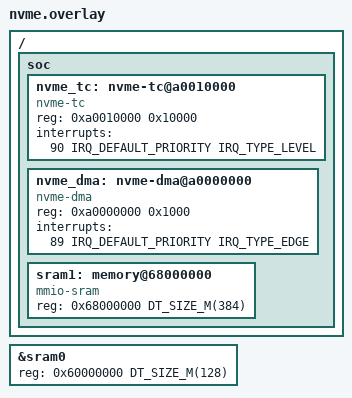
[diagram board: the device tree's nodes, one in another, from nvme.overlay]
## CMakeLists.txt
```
# Copyright 2021-2022 Western Digital Corporation or its affiliates
# Copyright 2021-2022 Antmicro

# SPDX-License-Identifier: Apache-2.0

cmake_minimum_required(VERSION 3.13.1)

set(DTC_OVERLAY_FILE "${CMAKE_CURRENT_SOURCE_DIR}/nvme.overlay")

include($ENV{ZEPHYR_BASE}/cmake/app/boilerplate.cmake NO_POLICY_SCOPE)

project(tc_sw)

target_sources(app PRIVATE src/main.c)
target_sources(app PRIVATE src/dma.c)
target_sources(app PRIVATE src/tc.c)
target_sources(app PRIVATE src/ramdisk.c)

target_sources(app PRIVATE src/rpmsg.c)
target_sources(app PRIVATE src/platform_info.c)
target_sources(app PRIVATE src/rsc_table.c)
target_sources(app PRIVATE src/zynqmp_r5_a53_rproc.c)

target_sources(app PRIVATE src/cmd.c)
target_sources(app PRIVATE src/cmds/identify.c)
target_sources(app PRIVATE src/cmds/get_log.c)
target_sources(app PRIVATE src/cmds/set_features.c)
target_sources(app PRIVATE src/cmds/queues.c)
target_sources(app PRIVATE src/cmds/read.c)
target_sources(app PRIVATE src/cmds/write.c)
target_sources(app PRIVATE src/cmds/vendor.c)

target_include_directories(app PRIVATE src)
target_include_directories(app PRIVATE ${GENERATED_DIR})

find_package( PythonInterp REQUIRED )

add_custom_target(
    generate_headers ALL
    COMMAND ${PYTHON_EXECUTABLE} ${REGGEN_DIR}/get_reg_fields.py
            ${NVME_SPEC_FILE} -f ${RPUAPP_GENERATED_DIR}/registers.json

    COMMAND ${PYTHON_EXECUTABLE} ${REGGEN_DIR}/get_reg_fields_zephyr.py
            ${RPUAPP_GENERATED_DIR}/registers.json -f ${RPUAPP_GENERATED_DIR}/nvme_reg_fields.h

    COMMAND ${PYTHON_EXECUTABLE} ${REGGEN_DIR}/get_reg_map_zephyr.py
            ${NVME_SPEC_FILE} -f ${RPUAPP_GENERATED_DIR}/nvme_reg_map.h

    COMMAND ${PYTHON_EXECUTABLE} ${REGGEN_DIR}/get_identify_struct.py
            ${NVME_SPEC_FILE} -f ${RPUAPP_GENERATED_DIR}/nvme_ident_fields.h

    BYPRODUCTS ${RPUAPP_GENERATED_DIR}/registers.json
                ${RPUAPP_GENERATED_DIR}/nvme_reg_fields.h
                ${RPUAPP_GENERATED_DIR}/nvme_reg_map.h
                ${RPUAPP_GENERATED_DIR}/nvme_ident_fields.h

    COMMENT "Generating NVMe headers"
)

add_dependencies(app generate_headers)
```

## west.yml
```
# Copyright 2021-2022 Western Digital Corporation or its affiliates
# Copyright 2021-2022 Antmicro
#
# SPDX-License-Identifier: Apache-2.0

manifest:
  defaults:
    remote: upstream

  self:
    path: rpu-app

  remotes:
    - name: upstream
      url-base: https://github.com/zephyrproject-rtos

  projects:
    - name: zephyr
      path: build/zephyr-sources/zephyr
      revision: 64dbc3e610d79db74f3ff1395fc9b1bf891f73c2
      import: true

    - name: libmetal
      revision: 6f2798ba1f6a63747baeb366ea50ccdc0cac2797
      path: build/zephyr-sources/modules/hal/libmetal
    - name: ci-tools
      revision: c083680dd5e281218ddb47d0ceac5c5fd5619749
      path: build/zephyr-sources/tools/ci-tools
    - name: net-tools
      revision: 30b7efa827b04d2e47840716b0372737fe7d6c92
      path: build/zephyr-sources/tools/net-tools
    - name: hal_atmel
      revision: 5690f5b84495c8b657ff204c5c827df1ab9e12e3
      path: build/zephyr-sources/modules/hal/atmel
    - name: civetweb
      revision: 99129c5efc907ea613c4b73ccff07581feb58a7a
      path: build/zephyr-sources/modules/lib/civetweb
    - name: esp-idf
      revision: 6835bfc741bf15e98fb7971293913f770df6081f
      path: build/zephyr-sources/modules/hal/esp-idf
    - name: fatfs
      revision: df96914dd989907f3a5de4cb95b116c2f305820d
      path: build/zephyr-sources/modules/fs/fatfs
    - name: hal_cypress
      revision: a12d92816a53a521d79cefcf5c38b9dc8a4fed6e
      path: build/zephyr-sources/modules/hal/cypress
    - name: hal_nordic
      revision: 64f3473398f9fba11059dd0c7ae969e74f74f356
      path: build/zephyr-sources/modules/hal/nordic
    - name: hal_openisa
      revision: 6416140c00f7e663752bd420ba89e3caefc1d70e
      path: build/zephyr-sources/modules/hal/openisa
    - name: hal_microchip
      revision: 85302959c0c659311cf90ac51d133e5ce19c9288
      path: build/zephyr-sources/modules/hal/microchip
    - name: hal_silabs
      revision: 9151e614c23997074acd1096a3e8a9e5c255d5b9
      path: build/zephyr-sources/modules/hal/silabs
    - name: hal_st
      revision: fa481784b3c49780f18d50bafe00390ccb62b2ec
      path: build/zephyr-sources/modules/hal/st
    - name: hal_stm32
      revision: 20776221282b6447c6330a041bc27758c8f593f3
      path: build/zephyr-sources/modules/hal/stm32
    - name: hal_ti
      revision: 7a82e93e14766ef6e42df9915ea2ab8e3b952a8b
      path: build/zephyr-sources/modules/hal/ti
    - name: lvgl
      revision: d4708d0a432e95f51bdc712591ba5295b751140c
      path: build/zephyr-sources/modules/lib/gui/lvgl
    - name: mbedtls
      revision: 4f1e8f5a78dc08aa42a47cc1ad059cce558c26c3
      path: build/zephyr-sources/modules/crypto/mbedtls
    - name: mcumgr
      revision: 84934959d2d1722a23b7e7e200191ae4a6f96168
      path: build/zephyr-sources/modules/lib/mcumgr
    - name: nffs
      revision: bc62a2fa9d98ddb5d633c932ea199bc68e10f194
      path: build/zephyr-sources/modules/fs/nffs
    - name: hal_nxp
      revision: c6ce9b7e8ddb501ca6d54e927e1602cb5f7a7183
      path: build/zephyr-sources/modules/hal/nxp
    - name: open-amp
      revision: 9b591b289e1f37339bd038b5a1f0e6c8ad39c63a
      path: build/zephyr-sources/modules/lib/open-amp
    - name: openthread
      revision: 882e7074b5986027b85cb4f3ba1dc563a11ca013
      path: build/zephyr-sources/modules/lib/openthread
    - name: segger
      revision: 6fcf61606d6012d2c44129edc033f59331e268bc
      path: build/zephyr-sources/modules/debug/segger
    - name: tinycbor
      path: build/zephyr-sources/modules/lib/tinycbor
      revision: 0fc68fceacd1efc1ce809c5880c380f3d98b7b6e
    - name: littlefs
      path: build/zephyr-sources/modules/fs/littlefs
      revision: fe9572dd5a9fcf93a249daa4233012692bd2881d
    - name: mipi-sys-t
      path: build/zephyr-sources/modules/debug/mipi-sys-t
      revision: baf51863f19f009b92e762115ba5572a5b996b92
```

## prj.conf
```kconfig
CONFIG_NEWLIB_LIBC=y
CONFIG_OPENAMP=y
CONFIG_HEAP_MEM_POOL_SIZE=4096
CONFIG_IPM=y
CONFIG_IPM_XLNX_ZYNQMP=y
CONFIG_LOG=y
CONFIG_LOG_MAX_LEVEL=4
CONFIG_LOG_BUFFER_SIZE=65536
CONFIG_LOG_FUNC_NAME_PREFIX_ERR=y
CONFIG_LOG_FUNC_NAME_PREFIX_WRN=y
CONFIG_LOG_FUNC_NAME_PREFIX_INF=y
CONFIG_LOG_FUNC_NAME_PREFIX_DBG=y
```

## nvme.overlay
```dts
/ {
	soc {
		nvme_tc: nvme-tc@a0010000 {
			compatible = "nvme-tc";
			reg = <0xa0010000 0x10000>;
			status = "okay";
			interrupts = <90 IRQ_DEFAULT_PRIORITY IRQ_TYPE_LEVEL>;
			interrupt-names = "host_write";
		};

		nvme_dma: nvme-dma@a0000000 {
			compatible = "nvme-dma";
			reg = <0xa0000000 0x1000>;
			status = "okay";
			interrupts = <89 IRQ_DEFAULT_PRIORITY IRQ_TYPE_EDGE>;
			interrupt-names = "dma_done";
		};

		sram1: memory@68000000 {
			compatible = "mmio-sram";
			reg = <0x68000000 DT_SIZE_M(384)>;
		};
	};
};

&sram0 {
	reg = <0x60000000 DT_SIZE_M(128)>;
};
```

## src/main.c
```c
/*
 * Copyright 2021-2022 Western Digital Corporation or its affiliates
 * Copyright 2021-2022 Antmicro
 *
 * SPDX-License-Identifier: Apache-2.0
 */

#include <zephyr.h>
#include <sys/printk.h>
#include <irq.h>

#include "main.h"
#include "dma.h"
#include "tc.h"
#include "ramdisk.h"
#include "rpmsg.h"

#include "platform_info.h"

#include <string.h>

#include <logging/log_ctrl.h>
#include <logging/log.h>

LOG_MODULE_REGISTER(NVME_LOGGER_NAME, NVME_LOGGER_LEVEL);
K_MEM_POOL_DEFINE(buffer_pool, PAGE_SIZE, NVME_BUFFER_SIZE, NVME_BUFFER_POOL_ENTRIES, PAGE_SIZE);

nvme_tc_priv_t *init(void)
{
	ramdisk_init();
	LOG_DBG("Init [1/6]: Ramdisk initialized");

	void *dma_priv = nvme_dma_init();
	LOG_DBG("Init [2/6]: DMA initialized");

	nvme_tc_priv_t *tc = nvme_tc_init(dma_priv);
	tc->buffer_pool = &buffer_pool;
	LOG_DBG("Init [3/6]: Target Controller (TC) initialized");

	nvme_dma_irq_init();
	LOG_DBG("Init [4/6]: DMA IRQ initialized");

	nvme_tc_irq_init();
	LOG_DBG("Init [5/6]: TC IRQs initialized");

	rpmsg_init(tc);
	LOG_DBG("Init [6/6]: Rpmsg initialized");

	return tc;
}

void main(void)
{
	log_init();
	LOG_INF("NVMe Controller FW for %s", CONFIG_BOARD);

	nvme_tc_priv_t *tc = init();

	LOG_INF("NVMe controller initialized");

	while(1) {
		platform_poll(tc->platform);
		k_sleep(100);
	}

	rpmsg_destroy_ept(&tc->lept);
}
```

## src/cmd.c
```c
/*
 * Copyright 2021-2022 Western Digital Corporation or its affiliates
 * Copyright 2021-2022 Antmicro
 *
 * SPDX-License-Identifier: Apache-2.0
 */

#include "cmd.h"
#include "dma.h"
#include "main.h"

#include <zephyr.h>
#include <sys/printk.h>
#include <openamp/open_amp.h>

#include <logging/log.h>
LOG_MODULE_DECLARE(NVME_LOGGER_NAME, NVME_LOGGER_LEVEL);

static inline void fill_cq_resp(nvme_cmd_priv_t *priv)
{
	nvme_sq_entry_base_t *sq = (nvme_sq_entry_base_t*)priv->sq_buf;
	nvme_cq_entry_t *cq = (nvme_cq_entry_t*)&priv->cq_buf;

	memset((void*)cq, 0, NVME_TC_CQ_ENTRY_SIZE);
	cq->sq_head = priv->tc->sq_head[priv->qid];
	cq->cid = sq->cdw0.cid;
}

static void handle_adm(nvme_cmd_priv_t *priv)
{
	nvme_sq_entry_base_t *cmd = (nvme_sq_entry_base_t*)priv->sq_buf;

	// LOG_DBG("Admin command (Opcode: %d)", cmd->cdw0.opc);
	switch(cmd->cdw0.opc) {
		case NVME_ADM_CMD_GET_LOG:
			LOG_DBG("Handling NVME_ADM_CMD_GET_LOG");
			nvme_cmd_adm_get_log(priv);
			break;
		case NVME_ADM_CMD_IDENTIFY:
			LOG_DBG("Handling NVME_ADM_CMD_IDENTIFY");
			nvme_cmd_adm_identify(priv);
			break;
		case NVME_ADM_CMD_SET_FEATURES:
			LOG_DBG("Handling NVME_ADM_CMD_SET_FEATURES");
			nvme_cmd_adm_set_features(priv);
			break;
		case NVME_ADM_CMD_CREATE_IO_SQ:
			LOG_DBG("Handling NVME_ADM_CMD_CREATE_IO_SQ");
			nvme_cmd_adm_create_sq(priv);
			break;
		case NVME_ADM_CMD_CREATE_IO_CQ:
			LOG_DBG("Handling NVME_ADM_CMD_CREATE_IO_CQ");
			nvme_cmd_adm_create_cq(priv);
			break;
		case NVME_ADM_CMD_DELETE_IO_SQ:
			LOG_DBG("Handling NVME_ADM_CMD_DELETE_IO_SQ");
			nvme_cmd_adm_delete_sq(priv);
			break;
		case NVME_ADM_CMD_DELETE_IO_CQ:
			LOG_DBG("Handling NVME_ADM_CMD_DELETE_IO_CQ");
			nvme_cmd_adm_delete_cq(priv);
			break;
		case NVME_ADM_CMD_FW_COMMIT: // Vendor command layout is compatible with FW commands and in the end FW commands are handled by the APU
			LOG_DBG("Handling NVME_ADM_CMD_FW_COMMIT");
			nvme_cmd_vendor(priv, 0);
			break;
		case NVME_ADM_CMD_FW_DOWNLOAD:
			LOG_DBG("Handling NVME_ADM_CMD_FW_DOWNLOAD");
			nvme_cmd_vendor(priv, 1);
			break;
		case NVME_ADM_CMD_KEEP_ALIVE:
			LOG_DBG("Handling NVME_ADM_CMD_KEEP_ALIVE");
		default:
			if(cmd->cdw0.opc >= NVME_ADM_CMD_VENDOR) {
				LOG_DBG("Handling NVME_ADM_CMD_VENDOR");
				nvme_cmd_vendor(priv, 0);
				break;
			}
			LOG_ERR("Unsupported Admin command! (Opcode: %d)", cmd->cdw0.opc);
			nvme_cmd_return(priv);
	}
}

static void handle_io(nvme_cmd_priv_t *priv)
{
	nvme_sq_entry_base_t *cmd = (nvme_sq_entry_base_t*)priv->sq_buf;

	// LOD_DBG("IO command (Opcode: %d)", cmd->cdw0.opc);
	switch(cmd->cdw0.opc) {
		case NVME_IO_CMD_FLUSH:
			LOG_DBG("Handling NVME_IO_CMD_FLUSH");
			nvme_cmd_return(priv);
			break;
		case NVME_IO_CMD_WRITE:
			LOG_DBG("Handling NVME_IO_CMD_WRITE");
			nvme_cmd_io_write(priv);
			break;
		case NVME_IO_CMD_READ:
			LOG_DBG("Handling NVME_IO_CMD_READ");
			nvme_cmd_io_read(priv);
			break;
		default:
			if(cmd->cdw0.opc >= NVME_IO_CMD_VENDOR) {
				LOG_DBG("Handling NVME_IO_CMD_VENDOR");
				nvme_cmd_vendor(priv, 0);
				break;
			}
			LOG_ERR("Unsupported IO Command! (Opcode: %d)", cmd->cdw0.opc);
			nvme_cmd_return(priv);
	}
}

void nvme_cmd_handler(void *cmd_priv, void *buf)
{
	nvme_cmd_priv_t *priv = (nvme_cmd_priv_t*)cmd_priv;
	fill_cq_resp(priv);

	if(priv->qid == ADM_QUEUE_ID)
		handle_adm(priv);
	else
		handle_io(priv);
}

static void cq_cb(void *cmd_priv, void *buf)
{
	nvme_cmd_priv_t *priv = (nvme_cmd_priv_t*)cmd_priv;
	LOG_INF("Sending completion interrupt to host");
	nvme_tc_cq_notify(priv->tc, priv->qid);
	k_mem_slab_free(&priv->tc->cmd_slab, &cmd_priv);
}

void nvme_cmd_return_cb(void *cmd_priv, void *buf)
{
	nvme_cmd_priv_t *priv = (nvme_cmd_priv_t*)cmd_priv;
	nvme_cmd_return(priv);
}

void nvme_cmd_return(nvme_cmd_priv_t *priv)
{
	nvme_cq_entry_t *cq = (nvme_cq_entry_t*)&priv->cq_buf;

	uint64_t cq_addr = nvme_tc_get_cq_addr(priv->tc, priv->qid);

	if (!cq_addr) {
		LOG_ERR("Completion Queue host memory address is invalid!");
		return;
	}

	// We know the correct phase only after obtaining next CQ entry address
	cq->p = priv->tc->cq_phase[priv->qid];

	nvme_dma_xfer_mem_to_host(priv->tc->dma_priv, (uint32_t)cq, cq_addr, NVME_TC_CQ_ENTRY_SIZE, cq_cb, (void*)priv);
}

static void transfer_chunk(nvme_cmd_priv_t *priv, uint64_t host_addr, uint32_t local_addr, uint32_t len)
{
	nvme_dma_xfer_cb *cb = NULL;
	void *arg = NULL;

	// const uint32_t lo = host_addr & 0xffffffff;
	// const uint32_t hi = (host_addr >> 32) & 0xffffffff;
	// LOG_DBG("Transferring data, host: %08x %08x, local: %08x, len: %d", hi, lo, local_addr, len);

	if(priv->xfer_len == len) {
		cb = priv->xfer_cb;
		arg = priv;
	}

	if(priv->dir == DIR_TO_HOST) {
		nvme_dma_xfer_mem_to_host(priv->tc->dma_priv, local_addr, host_addr, len, cb, arg);
	} else {
		nvme_dma_xfer_host_to_mem(priv->tc->dma_priv, host_addr, local_addr, len, cb, arg);
	}

	priv->xfer_len -= len;
	priv->xfer_buf += len;
}

static uint32_t calc_prp_size(uint64_t base, uint32_t mps, uint32_t len)
{
	uint32_t total = ((len + mps - 1) / mps) * sizeof(uint64_t);
	uint32_t page = mps - (base % mps);
	return (page > total) ? total : page;
}

static void prp_cb(void *cmd_priv, void *buf)
{
	nvme_cmd_priv_t *priv = (nvme_cmd_priv_t*)cmd_priv;
	uint64_t *prp_list = (uint64_t*)buf;
	const uint32_t mps = priv->tc->memory_page_size;
	const int prp_last = (priv->prp_size / sizeof(uint64_t)) - 1;
	int i = 0;

	LOG_DBG("List of PRPs transferred");

	while(priv->xfer_len > 0) {
		const int xfer_len = (mps > priv->xfer_len) ? priv->xfer_len : mps;

		if((i == prp_last) && (priv->xfer_len > mps)) { // We need to fetch another PRP list
			priv->prp_size = calc_prp_size(prp_list[prp_last], mps, priv->xfer_len);
			nvme_dma_xfer_host_to_mem(priv->tc->dma_priv, prp_list[prp_last], (uint32_t)buf, priv->prp_size, prp_cb, priv);
			LOG_DBG("Fetching list of PRPs (%d bytes)", priv->prp_size);
			return;
		}

		transfer_chunk(priv, prp_list[i++], priv->xfer_buf, xfer_len);
	}

	LOG_DBG("Finished transferring %d pages", i);

	k_mem_slab_free(&priv->tc->prp_slab, &buf);
}

static void transfer_data_with_prps(nvme_cmd_priv_t *priv)
{
	nvme_sq_entry_base_t *cmd = (nvme_sq_entry_base_t*)priv->sq_buf;
	uint64_t host_addr = cmd->dptr.prp.prp1;
	const int mps = priv->tc->memory_page_size;
	const int off = host_addr % mps;

	uint32_t xfer_len = ((mps - off) > priv->xfer_len) ? priv->xfer_len : (mps - off);

	transfer_chunk(priv, host_addr, priv->xfer_buf, xfer_len);

    printk("transfer_data_with_prps()\n"); // FIXME: This is a temporary workaround for a race condition.

	if(priv->xfer_len == 0) {
		return;
	}

	if(priv->xfer_len > mps) { // We need to fetch list of PRPs
		void *prp_buf;
		if(k_mem_slab_alloc(&priv->tc->prp_slab, (void**)&prp_buf, K_NO_WAIT) == 0) {
			priv->prp_size = calc_prp_size(cmd->dptr.prp.prp2, mps, priv->xfer_len);
			nvme_dma_xfer_host_to_mem(priv->tc->dma_priv, cmd->dptr.prp.prp2, (uint32_t)prp_buf, priv->prp_size, prp_cb, priv);
			LOG_DBG("Fetching list of PRPs (%d bytes)", priv->prp_size);
			return;
		} else {
			LOG_ERR("Failed to allocate PRP buffer!");
			nvme_cmd_return(priv);
			return;
		}
	} else { // Second PRP is in PRP2
		host_addr = cmd->dptr.prp.prp2;
		xfer_len = priv->xfer_len;
		transfer_chunk(priv, host_addr, priv->xfer_buf, xfer_len);
		return;
	}
}

int nvme_cmd_transfer_data(nvme_cmd_priv_t *priv)
{
	nvme_sq_entry_base_t *cmd = (nvme_sq_entry_base_t*)priv->sq_buf;
	uint8_t psdt = cmd->cdw0.psdt;

	if(psdt != 0) {
		LOG_ERR("Invalid PSDT value! (%d != 0)", psdt);
		return 1;
	} else {
		transfer_data_with_prps(priv);
		return 0;
	}

}

void nvme_cmd_get_data(nvme_cmd_priv_t *priv, void *ret_buf, uint32_t ret_len)
{
	priv->xfer_base = priv->xfer_buf = (uint32_t)ret_buf;
	priv->xfer_size = priv->xfer_len = ret_len;

	priv->dir = DIR_FROM_HOST;
	priv->xfer_cb = nvme_cmd_return_cb;

	if(nvme_cmd_transfer_data(priv))
		nvme_cmd_return(priv);
}

void nvme_cmd_return_data(nvme_cmd_priv_t *priv, void *ret_buf, uint32_t ret_len)
{
	priv->xfer_base = priv->xfer_buf = (uint32_t)ret_buf;
	priv->xfer_size = priv->xfer_len = ret_len;

	priv->dir = DIR_TO_HOST;
	priv->xfer_cb = nvme_cmd_return_cb;

	if(nvme_cmd_transfer_data(priv))
		nvme_cmd_return(priv);
}
```

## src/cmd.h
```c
/*
 * Copyright 2021-2022 Western Digital Corporation or its affiliates
 * Copyright 2021-2022 Antmicro
 *
 * SPDX-License-Identifier: Apache-2.0
 */

#ifndef NVME_CMD_H
#define NVME_CMD_H

#include <stdint.h>
#include <string.h>

#include "tc.h"

void nvme_cmd_handler(void *cmd_priv, void *cmd);

typedef struct nvme_cmd_cdw0 {
	uint32_t opc : 8;
	uint32_t fuse : 2;
	uint32_t rsvd : 4;
	uint32_t psdt : 2;
	uint32_t cid : 16;
} nvme_cmd_cdw0_t;

typedef struct nvme_cmd_prp {
	uint64_t prp1;
	uint64_t prp2;
} nvme_cmd_prp_t;

typedef struct __attribute__((packed)) nvme_cmd_sgl {
	uint8_t sgl_desc_type : 4;
	uint8_t sgl_desc_sub_type : 4;
	uint8_t rsvd[15];
} nvme_cmd_sgl_t;

typedef union nvme_cmd_dptr {
	nvme_cmd_prp_t prp;
	nvme_cmd_sgl_t sgl;
} nvme_cmd_dptr_t;

typedef struct nvme_sq_entry_base {
	nvme_cmd_cdw0_t cdw0;
	uint32_t nsid;
	uint32_t rsvd[2];
	uint64_t mptr;
	nvme_cmd_dptr_t dptr;
} nvme_sq_entry_base_t;

typedef struct nvme_sq_entry_vendor_base {
	nvme_sq_entry_base_t base;
	uint32_t ndt;
	uint32_t ndm;
} nvme_sq_entry_vendor_base_t;

typedef struct nvme_cq_entry {
	uint32_t cdw0;
	uint32_t rsvd;
	uint32_t sq_head : 16;
	uint32_t sq_id : 16;
	uint32_t cid : 16;
	uint32_t p : 1;
	uint32_t sc : 8;
	uint32_t sct : 3;
	uint32_t crd : 2;
	uint32_t m : 1;
	uint32_t dnr : 1;
} nvme_cq_entry_t;

#define NVME_ADM_CMD_GET_LOG		0x02
#define NVME_ADM_CMD_IDENTIFY		0x06
#define NVME_ADM_CMD_SET_FEATURES	0x09
#define NVME_ADM_CMD_CREATE_IO_SQ	0x01
#define NVME_ADM_CMD_CREATE_IO_CQ	0x05
#define NVME_ADM_CMD_DELETE_IO_SQ	0x00
#define NVME_ADM_CMD_DELETE_IO_CQ	0x04
#define NVME_ADM_CMD_FW_COMMIT		0x10
#define NVME_ADM_CMD_FW_DOWNLOAD	0x11
#define NVME_ADM_CMD_KEEP_ALIVE		0x18

#define NVME_ADM_CMD_VENDOR		0xC0

#define NVME_IO_CMD_FLUSH		0x00
#define NVME_IO_CMD_WRITE		0x01
#define NVME_IO_CMD_READ		0x02

#define NVME_IO_CMD_VENDOR		0x80

#define NVME_CMD_XFER_NONE		0x00
#define NVME_CMD_XFER_FROM_HOST		0x01
#define NVME_CMD_XFER_TO_HOST		0x02
#define NVME_CMD_XFER_BIDIR		0x03
#define NVME_CMD_XFER_MASK		0x03

int nvme_cmd_transfer_data(nvme_cmd_priv_t *priv);

void nvme_cmd_vendor(nvme_cmd_priv_t *priv, int zero_based);

void nvme_cmd_adm_identify(nvme_cmd_priv_t *priv);
void nvme_cmd_adm_get_log(nvme_cmd_priv_t *priv);
void nvme_cmd_adm_set_features(nvme_cmd_priv_t *priv);

void nvme_cmd_adm_create_sq(nvme_cmd_priv_t *priv);
void nvme_cmd_adm_create_cq(nvme_cmd_priv_t *priv);

void nvme_cmd_adm_delete_sq(nvme_cmd_priv_t *priv);
void nvme_cmd_adm_delete_cq(nvme_cmd_priv_t *priv);

void nvme_cmd_io_write(nvme_cmd_priv_t *priv);
void nvme_cmd_io_read(nvme_cmd_priv_t *priv);

void nvme_cmd_return(nvme_cmd_priv_t *priv);
void nvme_cmd_return_data(nvme_cmd_priv_t *priv, void *ret_buf, uint32_t ret_len);
void nvme_cmd_get_data(nvme_cmd_priv_t *priv, void *ret_buf, uint32_t ret_len);

#endif
```

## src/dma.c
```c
/*
 * Copyright 2021-2022 Western Digital Corporation or its affiliates
 * Copyright 2021-2022 Antmicro
 *
 * SPDX-License-Identifier: Apache-2.0
 */

#include "dma.h"
#include <zephyr.h>
#include <sys/printk.h>
#include <string.h>

#define DEBUG

typedef struct nvme_dma_priv {
	mem_addr_t base;

	uint32_t tx_xfers;
	uint32_t rx_xfers;

	struct k_fifo tx_fifo;
	struct k_fifo rx_fifo;

	bool tx_dma_running;
	bool rx_dma_running;

	struct k_mem_slab desc_slab;
} nvme_dma_priv_t;

typedef struct nvme_dma_xfer_def {
	void *fifo_reserved;
	nvme_dma_xfer_cb *cb;
	void *cb_arg;
	uint64_t host_addr;
	uint32_t local_addr;
	uint32_t len;
	uint32_t tag;
} nvme_dma_xfer_def_t;

nvme_dma_priv_t p_dma = {0};

char __aligned(16) desc_slab_buffer[sizeof(nvme_dma_xfer_def_t)*NVME_DMA_SLAB_ENTRIES];

struct k_timer nvme_dma_timer; // DMA timeout timer

static void nvme_dma_timeout (struct k_timer *timer) {

	nvme_dma_priv_t *priv = (nvme_dma_priv_t*)k_timer_user_data_get(timer);
	unsigned long long lock;

	LOG_ERR("DMA interrupt timeout!");

	lock = irq_lock();
	priv->rx_dma_running = false;
	// TODO: Retry transfer? Do something meaningful?
	irq_unlock(lock);

	k_timer_stop(timer);
}

static void nvme_dma_setup_xfer(nvme_dma_priv_t *priv, nvme_dma_xfer_def_t *desc, uint32_t off)
{
#ifdef DEBUG
	printk("Configuring DMA transfer\n");
#endif

	__DMB();

	sys_write32(desc->host_addr & 0xffffffff, priv->base + off + NVME_DMA_REG_PCIE_ADDRL);
	sys_write32((desc->host_addr >> 32) & 0xffffffff, priv->base + off + NVME_DMA_REG_PCIE_ADDRH);

	// We use 32-bit AXI addresses, upper 32-bits are ignored
	sys_write32(desc->local_addr, priv->base + off + NVME_DMA_REG_AXI_ADDRL);
	sys_write32(0, priv->base + off + NVME_DMA_REG_AXI_ADDRH);

	sys_write32(desc->len, priv->base + off + NVME_DMA_REG_LEN);

	// Writing tag starts transfer
	sys_write32(desc->tag, priv->base + off + NVME_DMA_REG_TAG);

	// Start the timeout timer
	// FIXME: Resolve the issue with incorrect CPU frequency set in Zephyr
	// and change the delay to something meaningful.
	k_timer_start(&nvme_dma_timer, K_SECONDS(100), K_FOREVER);
}

void nvme_dma_irq_handler(void *arg)
{
	nvme_dma_priv_t *priv = (nvme_dma_priv_t*)arg;
	unsigned long long lock;

	uint32_t read_status = sys_read32(priv->base + NVME_DMA_REG_STATUS + NVME_DMA_REG_READ_BASE);
	uint32_t write_status = sys_read32(priv->base + NVME_DMA_REG_STATUS + NVME_DMA_REG_WRITE_BASE);

	if(read_status & NVME_DMA_REG_STATUS_VALID) {
		nvme_dma_xfer_def_t *desc = k_fifo_get(&priv->rx_fifo, K_NO_WAIT);
		if(desc) {
			if(desc->cb)
				desc->cb(desc->cb_arg, (void*)desc->local_addr);
			k_mem_slab_free(&priv->desc_slab, (void**)&desc);
		} else {
			printk("Spurious DMA RX interrupt!\n");
		}

		lock = irq_lock();

		// Check if there is another transfer pending
		desc = k_fifo_peek_head(&priv->rx_fifo);
		if(desc)
			nvme_dma_setup_xfer(priv, desc, NVME_DMA_REG_READ_BASE);
		else {
			priv->rx_dma_running = false;
			k_timer_stop(&nvme_dma_timer);
		}

		irq_unlock(lock);
	}

	if(write_status & NVME_DMA_REG_STATUS_VALID) {
		nvme_dma_xfer_def_t *desc = k_fifo_get(&priv->tx_fifo, K_NO_WAIT);
		if(desc) {
			if(desc->cb)
				desc->cb(desc->cb_arg, (void*)desc->local_addr);
			k_mem_slab_free(&priv->desc_slab, (void**)&desc);
		} else {
			printk("Spurious DMA TX interrupt!\n");
		}

		lock = irq_lock();

		// Check if there is another transfer pending
		desc = k_fifo_peek_head(&priv->tx_fifo);
		if(desc)
			nvme_dma_setup_xfer(priv, desc, NVME_DMA_REG_WRITE_BASE);
		else {
			priv->tx_dma_running = false;
			k_timer_stop(&nvme_dma_timer);
		}

		irq_unlock(lock);
	}
}

void nvme_dma_irq_init(void)
{
	printk("Enabling DMA interrupts\n");
	IRQ_CONNECT(DT_INST_0_NVME_DMA_IRQ_0, DT_INST_0_NVME_DMA_IRQ_0_PRIORITY, nvme_dma_irq_handler, &p_dma, DT_INST_0_NVME_DMA_IRQ_0_FLAGS);
	irq_enable(DT_INST_0_NVME_DMA_IRQ_0);
	printk("DMA interrupts enabled\n");
}

void *nvme_dma_init(void)
{
	nvme_dma_priv_t *priv = &p_dma;

	priv->base = (mem_addr_t)DT_INST_0_NVME_DMA_BASE_ADDRESS;

	printk("Initializing private data\n");

	k_fifo_init(&priv->tx_fifo);
	k_fifo_init(&priv->rx_fifo);
	k_mem_slab_init(&priv->desc_slab, desc_slab_buffer, sizeof(nvme_dma_xfer_def_t), NVME_DMA_SLAB_ENTRIES);

	printk("Enabling DMA\n");
	sys_write32(1, priv->base + NVME_DMA_REG_EN);

	if(sys_read32(priv->base + NVME_DMA_REG_EN) == 1)
		printk("DMA enabled\n");
	else
		printk("Failed to enable DMA!\n");

	k_timer_init(&nvme_dma_timer, nvme_dma_timeout, NULL);
	k_timer_user_data_set(&nvme_dma_timer, (void*)priv);

	return (void*)priv;
}

static nvme_dma_xfer_def_t *nvme_dma_xfer_fill_desc(nvme_dma_priv_t *priv, uint64_t host, uint32_t local, uint32_t len, uint32_t tag, nvme_dma_xfer_cb *cb, void *cb_arg)
{
	nvme_dma_xfer_def_t *desc;

	if(k_mem_slab_alloc(&priv->desc_slab, (void**)&desc, K_NO_WAIT) == 0) {
		memset(desc, 0, sizeof(*desc));

		desc->host_addr = host;
		desc->local_addr = local;
		desc->len = len;
		desc->cb = cb;
		desc->cb_arg = cb_arg;
		desc->tag = tag;
	} else {
		printk("Failed to allocate DMA descriptor!\n");
		return NULL;
	}

	return desc;
}

int nvme_dma_xfer_host_to_mem(void* arg, uint64_t src, uint32_t dst, uint32_t len, nvme_dma_xfer_cb *cb, void *cb_arg)
{
	nvme_dma_priv_t *priv = (nvme_dma_priv_t*)arg;
	nvme_dma_xfer_def_t *desc = nvme_dma_xfer_fill_desc(priv, src, dst, len, 0xAA, cb, cb_arg);
	unsigned long long lock;

	printk("%s\n", __FUNCTION__);
	if(desc) {
		lock = irq_lock();
		k_fifo_put(&priv->rx_fifo, desc);
		if(!priv->rx_dma_running) {
			nvme_dma_setup_xfer(priv, desc, NVME_DMA_REG_READ_BASE);
			priv->rx_dma_running = true;
		}
		irq_unlock(lock);
		return 0;
	} else {
		return -ENOMEM;
	}
}

int nvme_dma_xfer_mem_to_host(void* arg, uint32_t src, uint64_t dst, uint32_t len, nvme_dma_xfer_cb *cb, void *cb_arg)
{
	nvme_dma_priv_t *priv = (nvme_dma_priv_t*)arg;
	nvme_dma_xfer_def_t *desc = nvme_dma_xfer_fill_desc(priv, dst, src, len, 0x55, cb, cb_arg);
	unsigned long long lock;

	if(desc) {
		lock = irq_lock();
		k_fifo_put(&priv->tx_fifo, desc);
		if(!priv->tx_dma_running) {
			nvme_dma_setup_xfer(priv, desc, NVME_DMA_REG_WRITE_BASE);
			priv->tx_dma_running = true;
		}
		irq_unlock(lock);
		return 0;
	} else {
		return -ENOMEM;
	}
}
```

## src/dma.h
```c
/*
 * Copyright 2021-2022 Western Digital Corporation or its affiliates
 * Copyright 2021-2022 Antmicro
 *
 * SPDX-License-Identifier: Apache-2.0
 */

#ifndef NVME_DMA_H
#define NVME_DMA_H

#define NVME_DMA_REG_EN	0x000

#define NVME_DMA_REG_READ_BASE		0x100
#define NVME_DMA_REG_WRITE_BASE		0x200

#define NVME_DMA_REG_PCIE_ADDRL		0x00
#define NVME_DMA_REG_PCIE_ADDRH		0x04
#define NVME_DMA_REG_AXI_ADDRL		0x08
#define NVME_DMA_REG_AXI_ADDRH		0x0c
#define NVME_DMA_REG_LEN		0x10
#define NVME_DMA_REG_TAG		0x14
#define NVME_DMA_REG_STATUS		0x18
#define NVME_DMA_REG_STATUS_VALID	(1<<31)

#define NVME_DMA_REG_RQ_COUNT		0x400
#define NVME_DMA_REG_RC_COUNT		0x404
#define NVME_DMA_REG_CQ_COUNT		0x408
#define NVME_DMA_REG_CC_COUNT		0x40c

#define NVME_DMA_SLAB_ENTRIES		(4096*16)

#include <stdint.h>

typedef void (nvme_dma_xfer_cb)(void *arg, void *buf);

void nvme_dma_irq_init(void);
void *nvme_dma_init(void);
int nvme_dma_xfer_host_to_mem(void *arg, uint64_t src, uint32_t dst, uint32_t len, nvme_dma_xfer_cb *cb, void *cb_arg);
int nvme_dma_xfer_mem_to_host(void *arg, uint32_t src, uint64_t dst, uint32_t len, nvme_dma_xfer_cb *cb, void *cb_arg);

#endif
```

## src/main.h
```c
#ifndef MAIN_H
#define MAIN_H

#define NVME_LOGGER_NAME  nvme
#define NVME_LOGGER_LEVEL 4

#endif /* MAIN_H */
```

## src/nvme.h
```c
#ifndef NVME_H
#define NVME_H

#include "nvme_reg_map.h"
#include "nvme_reg_fields.h"

#define DOORBELLS		5

#define DOORBELL_BASE		0x1000

#define DOORBELL_REG(n)		(DOORBELL_BASE+(n)*4)

#define DOORBELL_TAIL(n)	(DOORBELL_REG((n*2)))
#define DOORBELL_HEAD(n)	(DOORBELL_REG((n*2)+1))

#define NVME_TC_REG_ADM_TAIL	(DOORBELL_TAIL(0))
#define NVME_TC_REG_ADM_HEAD	(DOORBELL_HEAD(0))

#define NVME_TC_REG_IO_TAIL(n)	(DOORBELL_TAIL(n+1))
#define NVME_TC_REG_IO_HEAD(n)	(DOORBELL_HEAD(n+1))

#define NVME_TC_REG_IRQ_STA	(DOORBELL_TAIL(DOORBELLS))
#define NVME_TC_REG_IRQ_DAT	(DOORBELL_HEAD(DOORBELLS))

#define NVME_GET_FIELD(reg,name)	(((reg) >> NVME_TC_REG_##name##_SHIFT) & NVME_TC_REG_##name##_MASK)

#define NVME_SET_FIELD(reg, val, name)	(reg) |= (((val) & NVME_TC_REG_##name##_MASK) << NVME_TC_REG_##name##_SHIFT)

#define NVME_CLR_FIELD(reg, name)	NVME_SET_FIELD(reg, 0, name)

#define NVME_SHUTDOWN_PROCESSING	0x1
#define NVME_SHUTDOWN_COMPLETE		0x2

#endif
```

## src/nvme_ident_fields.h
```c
// Generated on 05/05/2021 10:16:15 with get_identify_struct.py, git rev 91c05fe
#ifndef NVME_IDENT_FIELDS_H
#define NVME_IDENT_FIELDS_H

#define	NVME_ID_FIELD_VID	0x0
#define	NVME_ID_FIELD_VID_SIZE	2
#define	NVME_ID_FIELD_SSVID	0x2
#define	NVME_ID_FIELD_SSVID_SIZE	2
#define	NVME_ID_FIELD_SN	0x4
#define	NVME_ID_FIELD_SN_SIZE	20
#define	NVME_ID_FIELD_MN	0x18
#define	NVME_ID_FIELD_MN_SIZE	40
#define	NVME_ID_FIELD_FR	0x40
#define	NVME_ID_FIELD_FR_SIZE	8
#define	NVME_ID_FIELD_RAB	0x48
#define	NVME_ID_FIELD_RAB_SIZE	1
#define	NVME_ID_FIELD_IEEE	0x49
#define	NVME_ID_FIELD_IEEE_SIZE	3
#define	NVME_ID_FIELD_CMIC	0x4c
#define	NVME_ID_FIELD_CMIC_SIZE	1
#define	NVME_ID_FIELD_MDTS	0x4d
#define	NVME_ID_FIELD_MDTS_SIZE	1
#define	NVME_ID_FIELD_CNTLID	0x4e
#define	NVME_ID_FIELD_CNTLID_SIZE	2
#define	NVME_ID_FIELD_VER	0x50
#define	NVME_ID_FIELD_VER_SIZE	4
#define	NVME_ID_FIELD_RTD3R	0x54
#define	NVME_ID_FIELD_RTD3R_SIZE	4
#define	NVME_ID_FIELD_RTD3E	0x58
#define	NVME_ID_FIELD_RTD3E_SIZE	4
#define	NVME_ID_FIELD_OAES	0x5c
#define	NVME_ID_FIELD_OAES_SIZE	4
#define	NVME_ID_FIELD_CTRATT	0x60
#define	NVME_ID_FIELD_CTRATT_SIZE	4
#define	NVME_ID_FIELD_RRLS	0x64
#define	NVME_ID_FIELD_RRLS_SIZE	2
#define	NVME_ID_FIELD_CNTRLTYPE	0x6f
#define	NVME_ID_FIELD_CNTRLTYPE_SIZE	1
#define	NVME_ID_FIELD_FGUID	0x70
#define	NVME_ID_FIELD_FGUID_SIZE	16
#define	NVME_ID_FIELD_CRDT1	0x80
#define	NVME_ID_FIELD_CRDT1_SIZE	2
#define	NVME_ID_FIELD_CRDT2	0x82
#define	NVME_ID_FIELD_CRDT2_SIZE	2
#define	NVME_ID_FIELD_CRDT3	0x84
#define	NVME_ID_FIELD_CRDT3_SIZE	2
#define	NVME_ID_FIELD_OACS	0x100
#define	NVME_ID_FIELD_OACS_SIZE	2
#define	NVME_ID_FIELD_ACL	0x102
#define	NVME_ID_FIELD_ACL_SIZE	1
#define	NVME_ID_FIELD_AERL	0x103
#define	NVME_ID_FIELD_AERL_SIZE	1
#define	NVME_ID_FIELD_FRMW	0x104
#define	NVME_ID_FIELD_FRMW_SIZE	1
#define	NVME_ID_FIELD_LPA	0x105
#define	NVME_ID_FIELD_LPA_SIZE	1
#define	NVME_ID_FIELD_ELPE	0x106
#define	NVME_ID_FIELD_ELPE_SIZE	1
#define	NVME_ID_FIELD_NPSS	0x107
#define	NVME_ID_FIELD_NPSS_SIZE	1
#define	NVME_ID_FIELD_AVSCC	0x108
#define	NVME_ID_FIELD_AVSCC_SIZE	1
#define	NVME_ID_FIELD_APSTA	0x109
#define	NVME_ID_FIELD_APSTA_SIZE	1
#define	NVME_ID_FIELD_WCTEMP	0x10a
#define	NVME_ID_FIELD_WCTEMP_SIZE	2
#define	NVME_ID_FIELD_CCTEMP	0x10c
#define	NVME_ID_FIELD_CCTEMP_SIZE	2
#define	NVME_ID_FIELD_MTFA	0x10e
#define	NVME_ID_FIELD_MTFA_SIZE	2
#define	NVME_ID_FIELD_HMPRE	0x110
#define	NVME_ID_FIELD_HMPRE_SIZE	4
#define	NVME_ID_FIELD_HMMIN	0x114
#define	NVME_ID_FIELD_HMMIN_SIZE	4
#define	NVME_ID_FIELD_TNVMCAP	0x118
#define	NVME_ID_FIELD_TNVMCAP_SIZE	16
#define	NVME_ID_FIELD_UNVMCAP	0x128
#define	NVME_ID_FIELD_UNVMCAP_SIZE	16
#define	NVME_ID_FIELD_RPMBS	0x138
#define	NVME_ID_FIELD_RPMBS_SIZE	4
#define	NVME_ID_FIELD_EDSTT	0x13c
#define	NVME_ID_FIELD_EDSTT_SIZE	2
#define	NVME_ID_FIELD_DSTO	0x13e
#define	NVME_ID_FIELD_DSTO_SIZE	1
#define	NVME_ID_FIELD_FWUG	0x13f
#define	NVME_ID_FIELD_FWUG_SIZE	1
#define	NVME_ID_FIELD_KAS	0x140
#define	NVME_ID_FIELD_KAS_SIZE	2
#define	NVME_ID_FIELD_HCTMA	0x142
#define	NVME_ID_FIELD_HCTMA_SIZE	2
#define	NVME_ID_FIELD_MNTMT	0x144
#define	NVME_ID_FIELD_MNTMT_SIZE	2
#define	NVME_ID_FIELD_MXTMT	0x146
#define	NVME_ID_FIELD_MXTMT_SIZE	2
#define	NVME_ID_FIELD_HMMINDS	0x14c
#define	NVME_ID_FIELD_HMMINDS_SIZE	4
#define	NVME_ID_FIELD_HMMAXD	0x150
#define	NVME_ID_FIELD_HMMAXD_SIZE	2
#define	NVME_ID_FIELD_NSETIDMAX	0x152
#define	NVME_ID_FIELD_NSETIDMAX_SIZE	2
#define	NVME_ID_FIELD_ENDGIDMAX	0x154
#define	NVME_ID_FIELD_ENDGIDMAX_SIZE	2
#define	NVME_ID_FIELD_ANATT	0x156
#define	NVME_ID_FIELD_ANATT_SIZE	1
#define	NVME_ID_FIELD_ANACAP	0x157
#define	NVME_ID_FIELD_ANACAP_SIZE	1
#define	NVME_ID_FIELD_ANAGRPMAX	0x158
#define	NVME_ID_FIELD_ANAGRPMAX_SIZE	4
#define	NVME_ID_FIELD_NANAGRPID	0x15c
#define	NVME_ID_FIELD_NANAGRPID_SIZE	4
#define	NVME_ID_FIELD_PELS	0x160
#define	NVME_ID_FIELD_PELS_SIZE	4
#define	NVME_ID_FIELD_SQES	0x200
#define	NVME_ID_FIELD_SQES_SIZE	1
#define	NVME_ID_FIELD_CQES	0x201
#define	NVME_ID_FIELD_CQES_SIZE	1
#define	NVME_ID_FIELD_MAXCMD	0x202
#define	NVME_ID_FIELD_MAXCMD_SIZE	2
#define	NVME_ID_FIELD_NN	0x204
#define	NVME_ID_FIELD_NN_SIZE	4
#define	NVME_ID_FIELD_ONCS	0x208
#define	NVME_ID_FIELD_ONCS_SIZE	2
#define	NVME_ID_FIELD_FUSES	0x20a
#define	NVME_ID_FIELD_FUSES_SIZE	2
#define	NVME_ID_FIELD_FNA	0x20c
#define	NVME_ID_FIELD_FNA_SIZE	1
#define	NVME_ID_FIELD_VWC	0x20d
#define	NVME_ID_FIELD_VWC_SIZE	1
#define	NVME_ID_FIELD_AWUN	0x20e
#define	NVME_ID_FIELD_AWUN_SIZE	2
#define	NVME_ID_FIELD_AWUPF	0x210
#define	NVME_ID_FIELD_AWUPF_SIZE	2
#define	NVME_ID_FIELD_NVSCC	0x212
#define	NVME_ID_FIELD_NVSCC_SIZE	1
#define	NVME_ID_FIELD_NWPC	0x213
#define	NVME_ID_FIELD_NWPC_SIZE	1
#define	NVME_ID_FIELD_ACWU	0x214
#define	NVME_ID_FIELD_ACWU_SIZE	2
#define	NVME_ID_FIELD_SGLS	0x218
#define	NVME_ID_FIELD_SGLS_SIZE	4
#define	NVME_ID_FIELD_MNAN	0x21c
#define	NVME_ID_FIELD_MNAN_SIZE	4
#define	NVME_ID_FIELD_SUBNQN	0x300
#define	NVME_ID_FIELD_SUBNQN_SIZE	256
#endif
```

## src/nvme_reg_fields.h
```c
// Generated on 23/04/2021 13:41:04 with get_reg_fields_zephyr.py, git rev 1ef89dd
#ifndef NVME_REG_FIELDS_H
#define NVME_REG_FIELDS_H

#define NVME_TC_REG_CAP_0_TO_MASK	0xff
#define NVME_TC_REG_CAP_0_TO_SHIFT	24
#define NVME_TC_REG_CAP_0_Reserved_2_MASK	0x1f
#define NVME_TC_REG_CAP_0_Reserved_2_SHIFT	19
#define NVME_TC_REG_CAP_0_AMS_MASK	0x3
#define NVME_TC_REG_CAP_0_AMS_SHIFT	17
#define NVME_TC_REG_CAP_0_CQR	(1<<16)
#define NVME_TC_REG_CAP_0_MQES_MASK	0xffff
#define NVME_TC_REG_CAP_0_MQES_SHIFT	0
#define NVME_TC_REG_CAP_1_Reserved_0_MASK	0x3f
#define NVME_TC_REG_CAP_1_Reserved_0_SHIFT	26
#define NVME_TC_REG_CAP_1_CMBS	(1<<25)
#define NVME_TC_REG_CAP_1_PMRS	(1<<24)
#define NVME_TC_REG_CAP_1_MPSMAX_MASK	0xf
#define NVME_TC_REG_CAP_1_MPSMAX_SHIFT	20
#define NVME_TC_REG_CAP_1_MPSMIN_MASK	0xf
#define NVME_TC_REG_CAP_1_MPSMIN_SHIFT	16
#define NVME_TC_REG_CAP_1_Reserved_1_MASK	0x3
#define NVME_TC_REG_CAP_1_Reserved_1_SHIFT	14
#define NVME_TC_REG_CAP_1_BPS	(1<<13)
#define NVME_TC_REG_CAP_1_CSS_MASK	0xff
#define NVME_TC_REG_CAP_1_CSS_SHIFT	5
#define NVME_TC_REG_CAP_1_NSSRS	(1<<4)
#define NVME_TC_REG_CAP_1_DSTRD_MASK	0xf
#define NVME_TC_REG_CAP_1_DSTRD_SHIFT	0
#define NVME_TC_REG_VS_MJR_MASK	0xffff
#define NVME_TC_REG_VS_MJR_SHIFT	16
#define NVME_TC_REG_VS_MNR_MASK	0xff
#define NVME_TC_REG_VS_MNR_SHIFT	8
#define NVME_TC_REG_VS_TER_MASK	0xff
#define NVME_TC_REG_VS_TER_SHIFT	0
#define NVME_TC_REG_INTMS_IVMS_MASK	0xffffffff
#define NVME_TC_REG_INTMS_IVMS_SHIFT	0
#define NVME_TC_REG_INTMC_IVMC_MASK	0xffffffff
#define NVME_TC_REG_INTMC_IVMC_SHIFT	0
#define NVME_TC_REG_CC_Reserved_0_MASK	0xff
#define NVME_TC_REG_CC_Reserved_0_SHIFT	24
#define NVME_TC_REG_CC_IOCQES_MASK	0xf
#define NVME_TC_REG_CC_IOCQES_SHIFT	20
#define NVME_TC_REG_CC_IOSQES_MASK	0xf
#define NVME_TC_REG_CC_IOSQES_SHIFT	16
#define NVME_TC_REG_CC_SHN_MASK	0x3
#define NVME_TC_REG_CC_SHN_SHIFT	14
#define NVME_TC_REG_CC_AMS_MASK	0x7
#define NVME_TC_REG_CC_AMS_SHIFT	11
#define NVME_TC_REG_CC_MPS_MASK	0xf
#define NVME_TC_REG_CC_MPS_SHIFT	7
#define NVME_TC_REG_CC_CSS_MASK	0x7
#define NVME_TC_REG_CC_CSS_SHIFT	4
#define NVME_TC_REG_CC_Reserved_1_MASK	0x7
#define NVME_TC_REG_CC_Reserved_1_SHIFT	1
#define NVME_TC_REG_CC_EN	(1<<0)
#define NVME_TC_REG_CSTS_Reserved_0_MASK	0x3ffffff
#define NVME_TC_REG_CSTS_Reserved_0_SHIFT	6
#define NVME_TC_REG_CSTS_PP	(1<<5)
#define NVME_TC_REG_CSTS_NSSRO	(1<<4)
#define NVME_TC_REG_CSTS_SHST_MASK	0x3
#define NVME_TC_REG_CSTS_SHST_SHIFT	2
#define NVME_TC_REG_CSTS_CFS	(1<<1)
#define NVME_TC_REG_CSTS_RDY	(1<<0)
#define NVME_TC_REG_NSSR_NSSRC_MASK	0xffffffff
#define NVME_TC_REG_NSSR_NSSRC_SHIFT	0
#define NVME_TC_REG_AQA_Reserved_0_MASK	0xf
#define NVME_TC_REG_AQA_Reserved_0_SHIFT	28
#define NVME_TC_REG_AQA_ACQS_MASK	0xfff
#define NVME_TC_REG_AQA_ACQS_SHIFT	16
#define NVME_TC_REG_AQA_Reserved_1_MASK	0xf
#define NVME_TC_REG_AQA_Reserved_1_SHIFT	12
#define NVME_TC_REG_AQA_ASQS_MASK	0xfff
#define NVME_TC_REG_AQA_ASQS_SHIFT	0
#define NVME_TC_REG_ASQ_0_ASQB_MASK	0xfffff
#define NVME_TC_REG_ASQ_0_ASQB_SHIFT	12
#define NVME_TC_REG_ASQ_0_Reserved_0_MASK	0xfff
#define NVME_TC_REG_ASQ_0_Reserved_0_SHIFT	0
#define NVME_TC_REG_ASQ_1_ASQB_MASK	0xffffffff
#define NVME_TC_REG_ASQ_1_ASQB_SHIFT	0
#define NVME_TC_REG_ACQ_0_ACQB_MASK	0xfffff
#define NVME_TC_REG_ACQ_0_ACQB_SHIFT	12
#define NVME_TC_REG_ACQ_0_Reserved_0_MASK	0xfff
#define NVME_TC_REG_ACQ_0_Reserved_0_SHIFT	0
#define NVME_TC_REG_ACQ_1_ACQB_MASK	0xffffffff
#define NVME_TC_REG_ACQ_1_ACQB_SHIFT	0
#define NVME_TC_REG_CMBLOC_OFST_MASK	0xfffff
#define NVME_TC_REG_CMBLOC_OFST_SHIFT	12
#define NVME_TC_REG_CMBLOC_Reserved_0_MASK	0x7
#define NVME_TC_REG_CMBLOC_Reserved_0_SHIFT	9
#define NVME_TC_REG_CMBLOC_CQDA	(1<<8)
#define NVME_TC_REG_CMBLOC_CDMMMS	(1<<7)
#define NVME_TC_REG_CMBLOC_CDPCILS	(1<<6)
#define NVME_TC_REG_CMBLOC_CDPMLS	(1<<5)
#define NVME_TC_REG_CMBLOC_CQPDS	(1<<4)
#define NVME_TC_REG_CMBLOC_CQMMS	(1<<3)
#define NVME_TC_REG_CMBLOC_BIR_MASK	0x7
#define NVME_TC_REG_CMBLOC_BIR_SHIFT	0
#define NVME_TC_REG_CMBSZ_SZ_MASK	0xfffff
#define NVME_TC_REG_CMBSZ_SZ_SHIFT	12
#define NVME_TC_REG_CMBSZ_SZU_MASK	0xf
#define NVME_TC_REG_CMBSZ_SZU_SHIFT	8
#define NVME_TC_REG_CMBSZ_Reserved_0_MASK	0x7
#define NVME_TC_REG_CMBSZ_Reserved_0_SHIFT	5
#define NVME_TC_REG_CMBSZ_WDS	(1<<4)
#define NVME_TC_REG_CMBSZ_RDS	(1<<3)
#define NVME_TC_REG_CMBSZ_LISTS	(1<<2)
#define NVME_TC_REG_CMBSZ_CQS	(1<<1)
#define NVME_TC_REG_CMBSZ_SQS	(1<<0)
#define NVME_TC_REG_BPINFO_ABPID	(1<<31)
#define NVME_TC_REG_BPINFO_Reserved_0_MASK	0x1f
#define NVME_TC_REG_BPINFO_Reserved_0_SHIFT	26
#define NVME_TC_REG_BPINFO_BRS_MASK	0x3
#define NVME_TC_REG_BPINFO_BRS_SHIFT	24
#define NVME_TC_REG_BPINFO_Reserved_1_MASK	0x1ff
#define NVME_TC_REG_BPINFO_Reserved_1_SHIFT	15
#define NVME_TC_REG_BPINFO_BPSZ_MASK	0x7fff
#define NVME_TC_REG_BPINFO_BPSZ_SHIFT	0
#define NVME_TC_REG_BPRSEL_BPID	(1<<31)
#define NVME_TC_REG_BPRSEL_Reserved_0	(1<<30)
#define NVME_TC_REG_BPRSEL_BPROF_MASK	0xfffff
#define NVME_TC_REG_BPRSEL_BPROF_SHIFT	10
#define NVME_TC_REG_BPRSEL_BPRSZ_MASK	0x3ff
#define NVME_TC_REG_BPRSEL_BPRSZ_SHIFT	0
#define NVME_TC_REG_BPMBL_0_BMBBA_MASK	0xfffff
#define NVME_TC_REG_BPMBL_0_BMBBA_SHIFT	12
#define NVME_TC_REG_BPMBL_0_Reserved_0_MASK	0xfff
#define NVME_TC_REG_BPMBL_0_Reserved_0_SHIFT	0
#define NVME_TC_REG_BPMBL_1_BMBBA_MASK	0xffffffff
#define NVME_TC_REG_BPMBL_1_BMBBA_SHIFT	0
#define NVME_TC_REG_CMBMSC_0_CBA_MASK	0xfffff
#define NVME_TC_REG_CMBMSC_0_CBA_SHIFT	12
#define NVME_TC_REG_CMBMSC_0_Reserved_0_MASK	0x3ff
#define NVME_TC_REG_CMBMSC_0_Reserved_0_SHIFT	2
#define NVME_TC_REG_CMBMSC_0_CMSE	(1<<1)
#define NVME_TC_REG_CMBMSC_0_CRE	(1<<0)
#define NVME_TC_REG_CMBMSC_1_CBA_MASK	0xffffffff
#define NVME_TC_REG_CMBMSC_1_CBA_SHIFT	0
#define NVME_TC_REG_CMBSTS_Reserved_0_MASK	0x7fffffff
#define NVME_TC_REG_CMBSTS_Reserved_0_SHIFT	1
#define NVME_TC_REG_CMBSTS_CBAI	(1<<0)
#define NVME_TC_REG_PMRCAP_Reserved_0_MASK	0x7f
#define NVME_TC_REG_PMRCAP_Reserved_0_SHIFT	25
#define NVME_TC_REG_PMRCAP_CMSS	(1<<24)
#define NVME_TC_REG_PMRCAP_PMRTO_MASK	0xff
#define NVME_TC_REG_PMRCAP_PMRTO_SHIFT	16
#define NVME_TC_REG_PMRCAP_Reserved_1_MASK	0x3
#define NVME_TC_REG_PMRCAP_Reserved_1_SHIFT	14
#define NVME_TC_REG_PMRCAP_PMRWBM_MASK	0xf
#define NVME_TC_REG_PMRCAP_PMRWBM_SHIFT	10
#define NVME_TC_REG_PMRCAP_PMRTU_MASK	0x3
#define NVME_TC_REG_PMRCAP_PMRTU_SHIFT	8
#define NVME_TC_REG_PMRCAP_BIR_MASK	0x7
#define NVME_TC_REG_PMRCAP_BIR_SHIFT	5
#define NVME_TC_REG_PMRCAP_WDS	(1<<4)
#define NVME_TC_REG_PMRCAP_RDS	(1<<3)
#define NVME_TC_REG_PMRCAP_Reserved_2_MASK	0x7
#define NVME_TC_REG_PMRCAP_Reserved_2_SHIFT	0
#define NVME_TC_REG_PMRCTL_Reserved_0_MASK	0x7fffffff
#define NVME_TC_REG_PMRCTL_Reserved_0_SHIFT	1
#define NVME_TC_REG_PMRCTL_EN	(1<<0)
#define NVME_TC_REG_PMRSTS_Reserved_0_MASK	0x7ffff
#define NVME_TC_REG_PMRSTS_Reserved_0_SHIFT	13
#define NVME_TC_REG_PMRSTS_CBAI	(1<<12)
#define NVME_TC_REG_PMRSTS_HSTS_MASK	0x7
#define NVME_TC_REG_PMRSTS_HSTS_SHIFT	9
#define NVME_TC_REG_PMRSTS_NRDY	(1<<8)
#define NVME_TC_REG_PMRSTS_ERR_MASK	0xff
#define NVME_TC_REG_PMRSTS_ERR_SHIFT	0
#define NVME_TC_REG_PMREBS_PMRWBZ_MASK	0xffffff
#define NVME_TC_REG_PMREBS_PMRWBZ_SHIFT	8
#define NVME_TC_REG_PMREBS_Reserved_0_MASK	0x7
#define NVME_TC_REG_PMREBS_Reserved_0_SHIFT	5
#define NVME_TC_REG_PMREBS_RBB	(1<<4)
#define NVME_TC_REG_PMREBS_PMRSZU_MASK	0xf
#define NVME_TC_REG_PMREBS_PMRSZU_SHIFT	0
#define NVME_TC_REG_PMRSWTP_PMRSWTV_MASK	0xffffff
#define NVME_TC_REG_PMRSWTP_PMRSWTV_SHIFT	8
#define NVME_TC_REG_PMRSWTP_Reserved_0_MASK	0xf
#define NVME_TC_REG_PMRSWTP_Reserved_0_SHIFT	4
#define NVME_TC_REG_PMRSWTP_PMRSWTU_MASK	0xf
#define NVME_TC_REG_PMRSWTP_PMRSWTU_SHIFT	0
#define NVME_TC_REG_PMRMSC_0_CBA_MASK	0xfffff
#define NVME_TC_REG_PMRMSC_0_CBA_SHIFT	12
#define NVME_TC_REG_PMRMSC_0_Reserved_0_MASK	0x3ff
#define NVME_TC_REG_PMRMSC_0_Reserved_0_SHIFT	2
#define NVME_TC_REG_PMRMSC_0_CMSE	(1<<1)
#define NVME_TC_REG_PMRMSC_0_Reserved_1	(1<<0)
#define NVME_TC_REG_PMRMSC_1_CBA_MASK	0xffffffff
#define NVME_TC_REG_PMRMSC_1_CBA_SHIFT	0
#define NVME_TC_REG_SQ0TDBL_Reserved_0_MASK	0xffff
#define NVME_TC_REG_SQ0TDBL_Reserved_0_SHIFT	16
#define NVME_TC_REG_SQ0TDBL_SQT_MASK	0xffff
#define NVME_TC_REG_SQ0TDBL_SQT_SHIFT	0

#endif
```

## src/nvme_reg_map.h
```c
// Generated on 23/04/2021 13:41:10 with get_reg_map_zephyr.py, git rev 1ef89dd
#ifndef NVME_REG_MAP_H
#define NVME_REG_MAP_H

#define	NVME_TC_REG_CAP_0	0x0
#define	NVME_TC_REG_CAP_1	0x4
#define	NVME_TC_REG_VS	0x8
#define	NVME_TC_REG_INTMS	0xc
#define	NVME_TC_REG_INTMC	0x10
#define	NVME_TC_REG_CC	0x14
#define	NVME_TC_REG_CSTS	0x1c
#define	NVME_TC_REG_NSSR	0x20
#define	NVME_TC_REG_AQA	0x24
#define	NVME_TC_REG_ASQ_0	0x28
#define	NVME_TC_REG_ASQ_1	0x2c
#define	NVME_TC_REG_ACQ_0	0x30
#define	NVME_TC_REG_ACQ_1	0x34
#define	NVME_TC_REG_CMBLOC	0x38
#define	NVME_TC_REG_CMBSZ	0x3c
#define	NVME_TC_REG_BPINFO	0x40
#define	NVME_TC_REG_BPRSEL	0x44
#define	NVME_TC_REG_BPMBL_0	0x48
#define	NVME_TC_REG_BPMBL_1	0x4c
#define	NVME_TC_REG_CMBMSC_0	0x50
#define	NVME_TC_REG_CMBMSC_1	0x54
#define	NVME_TC_REG_CMBSTS	0x58
#define	NVME_TC_REG_PMRCAP	0xe00
#define	NVME_TC_REG_PMRCTL	0xe04
#define	NVME_TC_REG_PMRSTS	0xe08
#define	NVME_TC_REG_PMREBS	0xe0c
#define	NVME_TC_REG_PMRSWTP	0xe10
#define	NVME_TC_REG_PMRMSC_0	0xe14
#define	NVME_TC_REG_PMRMSC_1	0xe18

#endif
```

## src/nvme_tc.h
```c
#ifndef NVME_TC_H
#define NVME_TC_H

#define NVME_TC_CC_REG	0x14
#define NVME_TC_CSTS_REG 0x1c

#define NVME_TC_CC_EN	0x1

#define NVME_TC_IRQ_STA_REG	0x1028
#define NVME_TC_IRQ_DAT_REG	0x102c

#endif
```

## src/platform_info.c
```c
/*
 * Copyright 2021-2022 Western Digital Corporation or its affiliates
 * Copyright 2021-2022 Antmicro
 *
 * SPDX-License-Identifier: Apache-2.0
 */

#include <errno.h>
#include <metal/atomic.h>
#include <metal/assert.h>
#include <metal/device.h>
#include <metal/sys.h>
#include <metal/irq.h>
#include <metal/utilities.h>
#include <openamp/rpmsg_virtio.h>
#include "platform_info.h"
#include "rsc_table.h"

/* Cortex R5 memory attributes */
#define DEVICE_SHARED		0x00000001U /* device, shareable */
#define DEVICE_NONSHARED	0x00000010U /* device, non shareable */
#define NORM_NSHARED_NCACHE	0x00000008U /* Non cacheable  non shareable */
#define NORM_SHARED_NCACHE	0x0000000CU /* Non cacheable shareable */
#define	PRIV_RW_USER_RW		(0x00000003U<<8U) /* Full Access */

#define SHARED_MEM_PA  0x7ff00000UL
#define SHARED_MEM_SIZE  0x100000UL
#define SHARED_BUF_OFFSET 0x8000UL

#define _rproc_wait() ({ \
		__asm volatile("wfi"); \
	})

static struct remoteproc_priv rproc_priv;

static struct remoteproc rproc_inst;

/* processor operations from r5 to a53. It defines
 * notification operation and remote processor managementi operations.
 */
extern struct remoteproc_ops zynqmp_r5_a53_proc_ops;

/* RPMsg virtio shared buffer pool */
static struct rpmsg_virtio_shm_pool shpool;

static struct remoteproc *
platform_create_proc(int proc_index, int rsc_index)
{
	void *rsc_table;
	int rsc_size;
	int ret;
	metal_phys_addr_t pa;

	(void) proc_index;
	rsc_table = get_resource_table(rsc_index, &rsc_size);

	/* Initialize remoteproc instance */
	if (!remoteproc_init(&rproc_inst, &zynqmp_r5_a53_proc_ops,
				&rproc_priv)) {
		printk("returned null\n");
		return NULL;
	}

	/*
	 * Mmap shared memories
	 * Or shall we constraint that they will be set as carved out
	 * in the resource table?
	 */
	/* mmap resource table */
	pa = (metal_phys_addr_t)rsc_table;
	(void *)remoteproc_mmap(&rproc_inst, &pa,
				NULL, rsc_size,
				NORM_NSHARED_NCACHE|PRIV_RW_USER_RW,
				&rproc_inst.rsc_io);
	/* mmap shared memory */
	pa = SHARED_MEM_PA;
	(void *)remoteproc_mmap(&rproc_inst, &pa,
				NULL, SHARED_MEM_SIZE,
				NORM_NSHARED_NCACHE|PRIV_RW_USER_RW,
				NULL);

	/* parse resource table to remoteproc */
	ret = remoteproc_set_rsc_table(&rproc_inst, rsc_table, rsc_size);
	if (ret) {
		printk("Failed to initialize remoteproc\n");
		remoteproc_remove(&rproc_inst);
		return NULL;
	}
	printk("Initialize remoteproc successfully.\n");

	return &rproc_inst;
}

int platform_init(void **platform)
{
	unsigned long proc_id = 0;
	unsigned long rsc_id = 0;
	struct remoteproc *rproc;

	if (!platform) {
		printk("Failed to initialize platform: NULL pointer to store platform data.\n");
		return -1;
	}
	rproc = platform_create_proc(proc_id, rsc_id);
	if (!rproc) {
		printk("Failed to create remoteproc device.\n");
		return -EINVAL;
	}
	*platform = rproc;
	return 0;
}

struct  rpmsg_device *
platform_create_rpmsg_vdev(void *platform, unsigned int vdev_index,
			   unsigned int role,
			   void (*rst_cb)(struct virtio_device *vdev),
			   rpmsg_ns_bind_cb ns_bind_cb)
{
	struct remoteproc *rproc = platform;
	struct rpmsg_virtio_device *rpmsg_vdev;
	struct virtio_device *vdev;
	void *shbuf;
	struct metal_io_region *shbuf_io;
	int ret;

	rpmsg_vdev = metal_allocate_memory(sizeof(*rpmsg_vdev));
	printk("allocated memory for rpmsg_vdev\n");
	if (!rpmsg_vdev)
		return NULL;
	shbuf_io = remoteproc_get_io_with_pa(rproc, SHARED_MEM_PA);
	if (!shbuf_io)
		return NULL;
	shbuf = metal_io_phys_to_virt(shbuf_io,
				      SHARED_MEM_PA + SHARED_BUF_OFFSET);

	printk("creating remoteproc virtio\n");
	vdev = remoteproc_create_virtio(rproc, vdev_index, role, rst_cb);
	if (!vdev) {
		printk("failed remoteproc_create_virtio\n");
		goto err1;
	}

	printk("initializing rpmsg shared buffer pool\n");
	/* Only RPMsg virtio master needs to initialize
	 * the shared buffers pool
	 */
	rpmsg_virtio_init_shm_pool(&shpool, shbuf,
				   (SHARED_MEM_SIZE - SHARED_BUF_OFFSET));

	printk("initializing rpmsg vdev\n");
	/* RPMsg virtio slave can set shared buffers pool argument to NULL */
	ret =  rpmsg_init_vdev(rpmsg_vdev, vdev, ns_bind_cb,
			       shbuf_io,
			       &shpool);
	if (ret) {
		printk("failed rpmsg_init_vdev\n");
		goto err2;
	}
	printk("initializing rpmsg vdev\n");
	return rpmsg_virtio_get_rpmsg_device(rpmsg_vdev);
err2:
	remoteproc_remove_virtio(rproc, vdev);
err1:
	metal_free_memory(rpmsg_vdev);
	return NULL;
}

int platform_poll(void *priv)
{
	struct remoteproc *rproc = priv;
	struct remoteproc_priv *prproc;
	unsigned int flags;
	int result;

	prproc = rproc->priv;
	flags = metal_irq_save_disable();
	result = atomic_flag_test_and_set(&prproc->ipi_nokick);
	metal_irq_restore_enable(flags);
	if (!result)
		remoteproc_get_notification(rproc, RSC_NOTIFY_ID_ANY);

	return 0;
}

void platform_cleanup(void *platform)
{
	struct remoteproc *rproc = platform;

	if (rproc)
		remoteproc_remove(rproc);
}

extern int zynqmp_r5_a53_proc_irq_handler(int, void *);

int irq_handler(int cpu_id)
{
	return zynqmp_r5_a53_proc_irq_handler(cpu_id, &rproc_inst);
}
```

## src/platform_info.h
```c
/*
 * Copyright 2021-2022 Western Digital Corporation or its affiliates
 * Copyright 2021-2022 Antmicro
 *
 * SPDX-License-Identifier: Apache-2.0
 */

#ifndef PLATFORM_INFO_H_
#define PLATFORM_INFO_H_

#include <openamp/remoteproc.h>
#include <openamp/virtio.h>
#include <openamp/rpmsg.h>

#if defined __cplusplus
extern "C" {
#endif

/* Cortex R5 memory attributes */
#define DEVICE_SHARED       0x00000001U /* device, shareable */
#define DEVICE_NONSHARED    0x00000010U /* device, non shareable */
#define NORM_NSHARED_NCACHE 0x00000008U /* Non cacheable  non shareable */
#define NORM_SHARED_NCACHE  0x0000000CU /* Non cacheable shareable */
#define PRIV_RW_USER_RW     (0x00000003U<<8U) /* Full Access */

struct remoteproc_priv {
	atomic_int ipi_nokick;
};

/**
 * platform_init - initialize the platform
 *
 * It will initialize the platform.
 *
 * @argc: number of arguments
 * @argv: array of the input arguments
 * @platform: pointer to store the platform data pointer
 *
 * return 0 for success or negative value for failure
 */
int platform_init(void **platform);

/**
 * platform_create_rpmsg_vdev - create rpmsg vdev
 *
 * It will create rpmsg virtio device, and returns the rpmsg virtio
 * device pointer.
 *
 * @platform: pointer to the private data
 * @vdev_index: index of the virtio device, there can more than one vdev
 *              on the platform.
 * @role: virtio master or virtio slave of the vdev
 * @rst_cb: virtio device reset callback
 * @ns_bind_cb: rpmsg name service bind callback
 *
 * return pointer to the rpmsg virtio device
 */
struct rpmsg_device *
platform_create_rpmsg_vdev(void *platform, unsigned int vdev_index,
			   unsigned int role,
			   void (*rst_cb)(struct virtio_device *vdev),
			   rpmsg_ns_bind_cb ns_bind_cb);

/**
 * platform_poll - platform poll function
 *
 * @platform: pointer to the platform
 *
 * return negative value for errors, otherwise 0.
 */
int platform_poll(void *platform);

/**
 * platform_cleanup - clean up the platform resource
 *
 * @platform: pointer to the platform
 */
void platform_cleanup(void *platform);

int irq_handler(int cpu_id);

#if defined __cplusplus
}
#endif

#endif /* PLATFORM_INFO_H_ */
```
